AUTOSAR XML (schema 4-0-3)
package /ComponentTypes
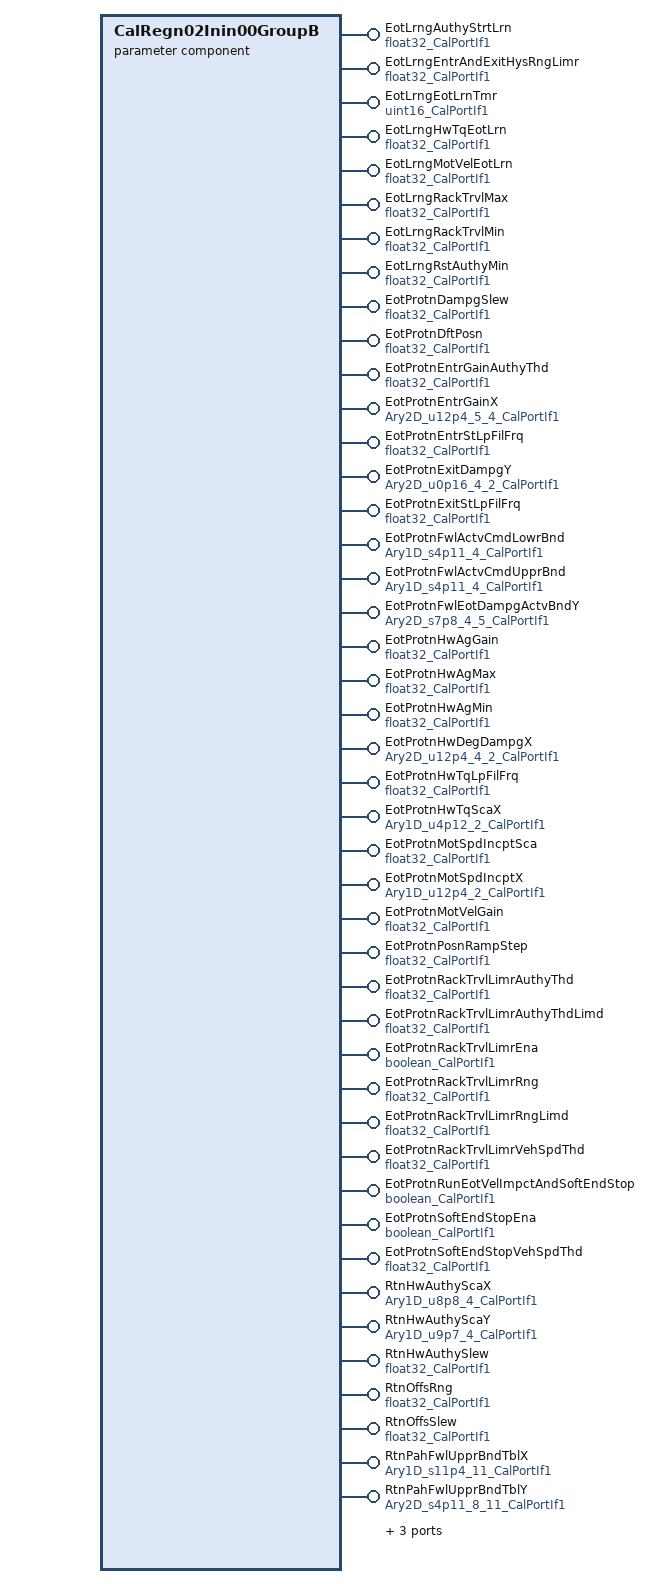
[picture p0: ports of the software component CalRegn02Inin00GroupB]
  parameter sw component type CalRegn02Inin00GroupB
    47 x provide port:
      EotLrngAuthyStrtLrn: parameter-provide-com-spec{init-value=1, parameter=Val}, provided-interface=float32_CalPortIf1
      EotLrngEntrAndExitHysRngLimr: parameter-provide-com-spec{init-value=3, parameter=Val}, provided-interface=float32_CalPortIf1
      EotLrngEotLrnTmr: parameter-provide-com-spec{init-value=100, parameter=Val}, provided-interface=uint16_CalPortIf1
      EotLrngHwTqEotLrn: parameter-provide-com-spec{init-value=2, parameter=Val}, provided-interface=float32_CalPortIf1
      EotLrngMotVelEotLrn: parameter-provide-com-spec{init-value=50, parameter=Val}, provided-interface=float32_CalPortIf1
      EotLrngRackTrvlMax: parameter-provide-com-spec{init-value=800, parameter=Val}, provided-interface=float32_CalPortIf1
      EotLrngRackTrvlMin: parameter-provide-com-spec{init-value=400, parameter=Val}, provided-interface=float32_CalPortIf1
      EotLrngRstAuthyMin: parameter-provide-com-spec{init-value=1, parameter=Val}, provided-interface=float32_CalPortIf1
      EotProtnDampgSlew: parameter-provide-com-spec{init-value=400, parameter=Val}, provided-interface=float32_CalPortIf1
      EotProtnDftPosn: parameter-provide-com-spec{init-value=100, parameter=Val}, provided-interface=float32_CalPortIf1
      EotProtnEntrGainAuthyThd: parameter-provide-com-spec{init-value=0.5, parameter=Val}, provided-interface=float32_CalPortIf1
      EotProtnEntrGainX: parameter-provide-com-spec{init-value=5 x [0, 480, 960, 1440], parameter=Ary2D}, provided-interface=Ary2D_u12p4_5_4_CalPortIf1
      EotProtnEntrStLpFilFrq: parameter-provide-com-spec{init-value=30, parameter=Val}, provided-interface=float32_CalPortIf1
      EotProtnExitDampgY: parameter-provide-com-spec{init-value=[[0, 262], [0, 262], [0, 262], [0, 262]], parameter=Ary2D}, provided-interface=Ary2D_u0p16_4_2_CalPortIf1
      EotProtnExitStLpFilFrq: parameter-provide-com-spec{init-value=5, parameter=Val}, provided-interface=float32_CalPortIf1
      EotProtnFwlActvCmdLowrBnd: parameter-provide-com-spec{init-value=[-512, -512, -512, -512], parameter=Ary1D}, provided-interface=Ary1D_s4p11_4_CalPortIf1
      EotProtnFwlActvCmdUpprBnd: parameter-provide-com-spec{init-value=[18022, 18022, 18022, 18022], parameter=Ary1D}, provided-interface=Ary1D_s4p11_4_CalPortIf1
      EotProtnFwlEotDampgActvBndY: parameter-provide-com-spec{init-value=[5 x 2253, 5 x 2253, 5 x 2253, 5 x 2253], parameter=Ary2D}, provided-interface=Ary2D_s7p8_4_5_CalPortIf1
      EotProtnHwAgGain: parameter-provide-com-spec{init-value=0.15, parameter=Val}, provided-interface=float32_CalPortIf1
      EotProtnHwAgMax: parameter-provide-com-spec{init-value=600, parameter=Val}, provided-interface=float32_CalPortIf1
      EotProtnHwAgMin: parameter-provide-com-spec{init-value=550, parameter=Val}, provided-interface=float32_CalPortIf1
      EotProtnHwDegDampgX: parameter-provide-com-spec{init-value=[[1920, 0], [1920, 0], [1920, 0], [1920, 0]], parameter=Ary2D}, provided-interface=Ary2D_u12p4_4_2_CalPortIf1
      EotProtnHwTqLpFilFrq: parameter-provide-com-spec{init-value=30, parameter=Val}, provided-interface=float32_CalPortIf1
      EotProtnHwTqScaX: parameter-provide-com-spec{init-value=[0, 4096], parameter=Ary1D}, provided-interface=Ary1D_u4p12_2_CalPortIf1
      EotProtnMotSpdIncptSca: parameter-provide-com-spec{init-value=0.02, parameter=Val}, provided-interface=float32_CalPortIf1
      EotProtnMotSpdIncptX: parameter-provide-com-spec{init-value=[800, 400], parameter=Ary1D}, provided-interface=Ary1D_u12p4_2_CalPortIf1
      EotProtnMotVelGain: parameter-provide-com-spec{init-value=0.29, parameter=Val}, provided-interface=float32_CalPortIf1
      EotProtnPosnRampStep: parameter-provide-com-spec{init-value=3, parameter=Val}, provided-interface=float32_CalPortIf1
      EotProtnRackTrvlLimrAuthyThd: parameter-provide-com-spec{init-value=1, parameter=Val}, provided-interface=float32_CalPortIf1
      EotProtnRackTrvlLimrAuthyThdLimd: parameter-provide-com-spec{init-value=1, parameter=Val}, provided-interface=float32_CalPortIf1
      EotProtnRackTrvlLimrEna: parameter-provide-com-spec{init-value=0, parameter=Logl}, provided-interface=boolean_CalPortIf1
      EotProtnRackTrvlLimrRng: parameter-provide-com-spec{init-value=90, parameter=Val}, provided-interface=float32_CalPortIf1
      EotProtnRackTrvlLimrRngLimd: parameter-provide-com-spec{init-value=20, parameter=Val}, provided-interface=float32_CalPortIf1
      EotProtnRackTrvlLimrVehSpdThd: parameter-provide-com-spec{init-value=20, parameter=Val}, provided-interface=float32_CalPortIf1
      EotProtnRunEotVelImpctAndSoftEndStop: parameter-provide-com-spec{init-value=0, parameter=Logl}, provided-interface=boolean_CalPortIf1
      EotProtnSoftEndStopEna: parameter-provide-com-spec{init-value=0, parameter=Logl}, provided-interface=boolean_CalPortIf1
      EotProtnSoftEndStopVehSpdThd: parameter-provide-com-spec{init-value=30, parameter=Val}, provided-interface=float32_CalPortIf1
      RtnHwAuthyScaX: parameter-provide-com-spec{init-value=[0, 128, 192, 256], parameter=Ary1D}, provided-interface=Ary1D_u8p8_4_CalPortIf1
      RtnHwAuthyScaY: parameter-provide-com-spec{init-value=[0, 0, 0, 128], parameter=Ary1D}, provided-interface=Ary1D_u9p7_4_CalPortIf1
      RtnHwAuthySlew: parameter-provide-com-spec{init-value=0.5, parameter=Val}, provided-interface=float32_CalPortIf1
      RtnOffsRng: parameter-provide-com-spec{init-value=17, parameter=Val}, provided-interface=float32_CalPortIf1
      RtnOffsSlew: parameter-provide-com-spec{init-value=0.04, parameter=Val}, provided-interface=float32_CalPortIf1
      RtnPahFwlUpprBndTblX: parameter-provide-com-spec{init-value=[-6400, -1600, 0, 800, 1600, 2400, 3200, 4000, 4800, 5600, 6400], parameter=Ary1D}, provided-interface=Ary1D_s11p4_11_CalPortIf1
      RtnPahFwlUpprBndTblY: parameter-provide-com-spec{init-value=8 x 11 x 18022, parameter=Ary2D}, provided-interface=Ary2D_s4p11_8_11_CalPortIf1
      RtnPahFwlVehSpd: parameter-provide-com-spec{init-value=[0, 384, 1280, 2560, 3840, 7680, 12800, 32640], parameter=Ary1D}, provided-interface=Ary1D_u9p7_8_CalPortIf1
      RtnTScaX: parameter-provide-com-spec{init-value=[-640, -560, -480, -320, -160, 0, 160, 320, 480, 640, 800, 960, 1120, 1440], parameter=Ary1D}, provided-interface=Ary1D_s11p4_14_CalPortIf1
      RtnTScaY: parameter-provide-com-spec{init-value=14 x 256, parameter=Ary1D}, provided-interface=Ary1D_u8p8_14_CalPortIf1
